# PT32G031xx register map
File version: 0.4
Registers are 32-bit, read-write, reset 0x0 unless marked. A register's access mark holds for its fields unless they carry their own. Offsets are from the block's base; [hi:lo] are bit positions.

## TIM3 — Basic timer
Base 0x40001400
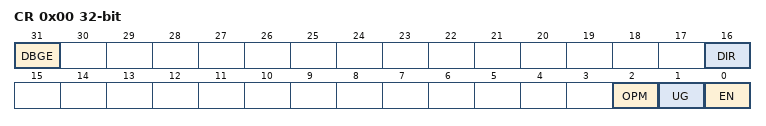
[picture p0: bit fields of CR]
0x00 CR — Control Register
  [31] DBGE — TIM debug
  [16] DIR — Direction
  [2] OPM — One-pulse mode
  [1] UG — Counter Update generation
  [0] EN — Counter enable
0x40 SR1 — Status Register 1
  [0] ARF — auto reload flag
0x48 IER1 — Interrupt Enable Register 1
  [0] ARIE — Auto reload interrupt enable
0x58 PSCR — Prescaler Register
  [31:0] PSC — Prescaler value
0x5C PCNTR — Prescaler Counter Register
  [31:0] CNT — Prescaler counter value
0x60 CNTR — Counter Register
  [31:0] CNT — Counter value
0x64 ARR — Auto Reload Register
  [31:0] ARR — Auto reload value

## TIM4 — Low power timer
Base 0x40001C00
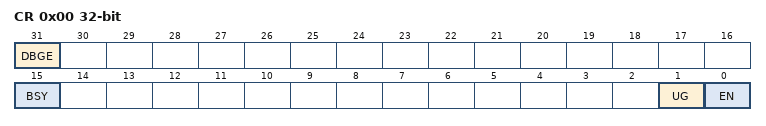
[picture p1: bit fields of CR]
0x00 CR access per field — Control Register
  [31] DBGE rw — TIM debug
  [15] BSY ro — TIM busy
  [1] UG rw — Counter Update generation
  [0] EN rw — Counter enable
0x40 SR1 — Status Register 1
  [0] ARF — auto reload flag
0x48 IER1 — Interrupt Enable Register 1
  [0] ARIE — Auto reload interrupt enable
0x58 PSCR — Prescaler Register
  [15:0] PSC — Prescaler value
0x5C PCNTR ro — Prescaler Counter Register
  [15:0] CNT — Prescaler counter value
0x60 CNTR ro — Counter Register
  [15:0] CNT — Counter value
0x64 ARR — Auto Reload Register
  [15:0] ARR — Auto reload value

## IWDG — Independent Watchdog
Base 0x40003000
0x00 RLR reset 0xFFFFFFFF — Reload Register
  [31:0] RL — Reload value
0x04 CNT ro reset 0xFFFFFFFF — Counter Register
  [31:0] CNT — Counter value
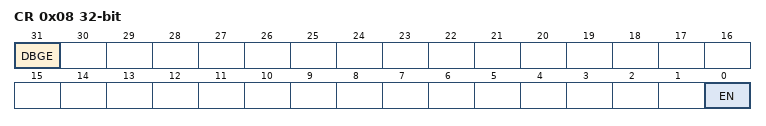
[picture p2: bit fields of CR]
0x08 CR — Control Register
  [31] DBGE — IWDG debug control
  [0] EN — enable
0x0C KR wo — Key Register
  [31:0] KEY — key value
0x10 SR ro — Status Register
  [0] HDF — hungry dog flag
0x33FC LR ro reset 0x1 — Lock Register
  [0] LOCK — lock status

## SPI0 — Serial peripheral interface
Base 0x40013000
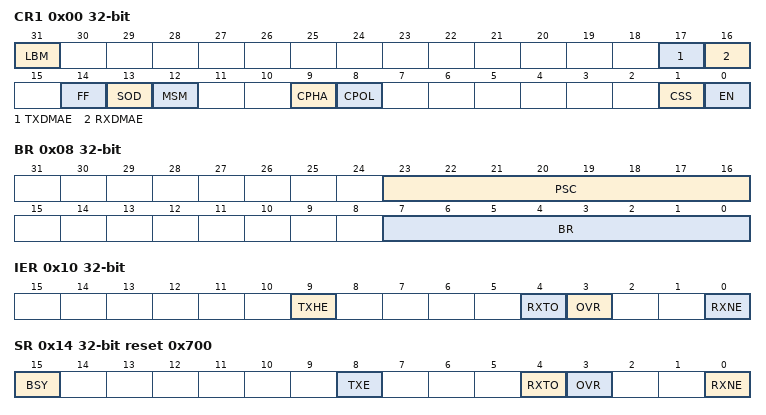
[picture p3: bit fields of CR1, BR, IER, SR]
0x00 CR1 — Control Register 1
  [31] LBM — loopback mode
  [17] TXDMAE — Tx DMA request enable
  [16] RXDMAE — Rx DMA request enable
  [14] FF — Frame format
  [13] SOD — SPI slave output disable
  [12] MSM — master-slave mode
  [9] CPHA — Clock phase
  [8] CPOL — Clock polarity
  [1] CSS — CSS control selection
  [0] EN — SPI Enable
0x04 CR2 reset 0x1 — Control Register 2
  [0] SWCS — Software control CSS
0x08 BR — Baud Rate Prescaler Register
  [23:16] PSC — Prescaler
  [7:0] BR — Baud rate control
0x10 IER — Interrupt Enable Register
  [9] TXHE — Transmit FIFO half empty interrupt enable
  [4] RXTO — Receive FIFO clear timeout interrupt enable
  [3] OVR — Receive FIFO overflow interrupt enable
  [0] RXNE — Receive FIFO not empty interrupt enable
0x14 SR access per field reset 0x700 — Status Register
  [15] BSY ro — busy flag
  [8] TXE read-wirte — Transmit FIFO empty flag
  [4] RXTO read-wirte — Receive FIFO clear timeout flag
  [3] OVR read-wirte — Receive FIFO overflow flag
  [0] RXNE ro — Receive FIFO not empty flag
0x20 DR — Data Register
  [7:0] DR — SPI data
0x24 DRR wo — Buffer/FIFO Data Reset Register
  [15:0] KEY — FIFO reset key

## I2C0 — Inter－Integrated Circuit
Base 0x40005400
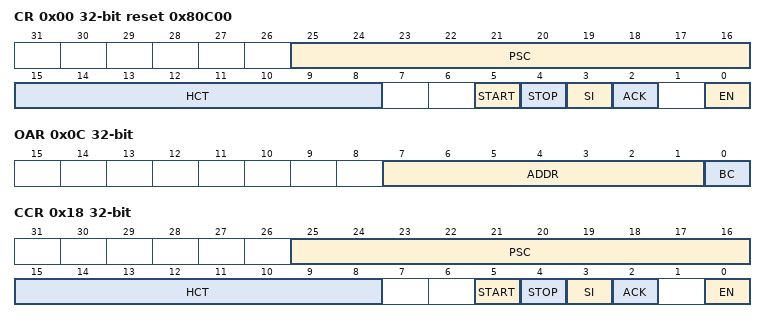
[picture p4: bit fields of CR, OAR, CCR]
0x00 CR access per field reset 0x80C00 — Control Register
  [25:16] PSC rw — Baud rate control
  [15:8] HCT rw — High level detection coefficient of time
  [5] START rw — Start generation
  [4] STOP rw — Stop generation
  [3] SI ro — I2C status flag
  [2] ACK rw — Acknowledge enable
  [0] EN rw — I2C enable
0x04 SR ro reset 0x1F — Status Register
  [4:0] SR — I2C bus status
0x08 DR — Data Register
  [7:0] DR — I2C data
0x0C OAR — Own Address Register
  [7:1] ADDR — I2C addr
  [0] BC — Broadcast response control
0x18 CCR wo — Control Clear Register
  [25:16] PSC — Clear prescaler
  [15:8] HCT — Clear high level detection time
  [5] START — Clear start generation
  [4] STOP — Clear stop generation
  [3] SI — Clear I2C interrupt flag
  [2] ACK — Clear Acknowledge control
  [0] EN — I2C disable
